# MSP432E401Y register map
Vendor: Texas Instruments; Series: MSP432E4; File version: 3.200
CPU: CM4 r1p2, little endian, no MPU, FPU, 3 interrupt priority bits
Registers are 32-bit, read-write, no defined reset value unless marked. A register's access mark holds for its fields unless they carry their own. Offsets are from the block's base; [hi:lo] are bit positions; {n}, {i} and the like mark numbered series.

## CCM0 — Register map for CCM0 peripheral
Base 0x44030204; register names take the prefix CCM0
0x00 CCMCGREQ — Cryptographic Modules Clock Gating Request

## CRC — Register map for CRC peripheral
Base 0x44030400
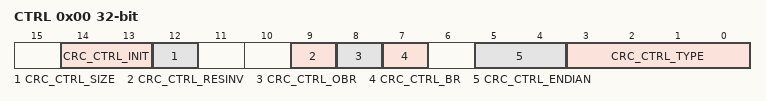
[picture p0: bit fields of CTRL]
0x00 CTRL — CRC Control
  [14:13] CRC_CTRL_INIT — CRC Initialization
    0=CRC_CTRL_INIT_SEED (Use the CRCSEED register context as the starting value); 2=Initialize to all '0s'; 3=Initialize to all '1s'
  [12] CRC_CTRL_SIZE — Input Data Size
  [9] CRC_CTRL_RESINV — Result Inverse Enable
  [8] CRC_CTRL_OBR — Output Reverse Enable
  [7] CRC_CTRL_BR — Bit reverse enable
  [5:4] CRC_CTRL_ENDIAN — Endian Control
    0=CRC_CTRL_ENDIAN_SBHW (Configuration unchanged. (B3, B2, B1, B0)); 1=CRC_CTRL_ENDIAN_SHW (Bytes are swapped in half-words but half-words are not swapped (B2, B3, B0, B1)); 2=CRC_CTRL_ENDIAN_SHWNB (Half-words are swapped but bytes are not swapped in half-word. (B1, B0, B3, B2)); 3=CRC_CTRL_ENDIAN_SBSW (Bytes are swapped in half-words and half-words are swapped. (B0, B1, B2, B3))
  [3:0] CRC_CTRL_TYPE — Operation Type
    0=CRC_CTRL_TYPE_P8055 (Polynomial 0x8005); 1=CRC_CTRL_TYPE_P1021 (Polynomial 0x1021); 2=CRC_CTRL_TYPE_P4C11DB7 (Polynomial 0x4C11DB7); 3=CRC_CTRL_TYPE_P1EDC6F41 (Polynomial 0x1EDC6F41); 8=CRC_CTRL_TYPE_TCPCHKSUM (TCP checksum)
0x10 CRCSEED — CRC SEED/Context
  [31:0] CRC_SEED_SEED — SEED/Context Value
0x14 CRCDIN — CRC Data Input
  [31:0] CRC_DIN_DATAIN — Data Input
0x18 CRCRSLTPP — CRC Post Processing Result
  [31:0] CRC_RSLTPP_RSLTPP — Post Processing Result

## SHAMD5 — Register map for SHAMD5 peripheral
Base 0x44034000; register names take the prefix SHAMD5
0x00 ODIGEST_A — SHA Outer Digest A
  [31:0] SHAMD5_ODIGEST_A_DATA — Digest/Key Data
0x04 ODIGEST_B — SHA Outer Digest B
  [31:0] SHAMD5_ODIGEST_B_DATA — Digest/Key Data
0x08 ODIGEST_C — SHA Outer Digest C
  [31:0] SHAMD5_ODIGEST_C_DATA — Digest/Key Data
0x0C ODIGEST_D — SHA Outer Digest D
  [31:0] SHAMD5_ODIGEST_D_DATA — Digest/Key Data
0x10 ODIGEST_E — SHA Outer Digest E
  [31:0] SHAMD5_ODIGEST_E_DATA — Digest/Key Data
0x14 ODIGEST_F — SHA Outer Digest F
  [31:0] SHAMD5_ODIGEST_F_DATA — Digest/Key Data
0x18 ODIGEST_G — SHA Outer Digest G
  [31:0] SHAMD5_ODIGEST_G_DATA — Digest/Key Data
0x1C ODIGEST_H — SHA Outer Digest H
  [31:0] SHAMD5_ODIGEST_H_DATA — Digest/Key Data
0x20 IDIGEST_A — SHA Inner Digest A
  [31:0] SHAMD5_IDIGEST_A_DATA — Digest/Key Data
0x24 IDIGEST_B — SHA Inner Digest B
  [31:0] SHAMD5_IDIGEST_B_DATA — Digest/Key Data
0x28 IDIGEST_C — SHA Inner Digest C
  [31:0] SHAMD5_IDIGEST_C_DATA — Digest/Key Data
0x2C IDIGEST_D — SHA Inner Digest D
  [31:0] SHAMD5_IDIGEST_D_DATA — Digest/Key Data
0x30 IDIGEST_E — SHA Inner Digest E
  [31:0] SHAMD5_IDIGEST_E_DATA — Digest/Key Data
0x34 IDIGEST_F — SHA Inner Digest F
  [31:0] SHAMD5_IDIGEST_F_DATA — Digest/Key Data
0x38 IDIGEST_G — SHA Inner Digest G
  [31:0] SHAMD5_IDIGEST_G_DATA — Digest/Key Data
0x3C IDIGEST_H — SHA Inner Digest H
  [31:0] SHAMD5_IDIGEST_H_DATA — Digest/Key Data
0x40 DIGEST_COUNT — SHA Digest Count
  [31:0] SHAMD5_DIGEST_COUNT — Digest Count
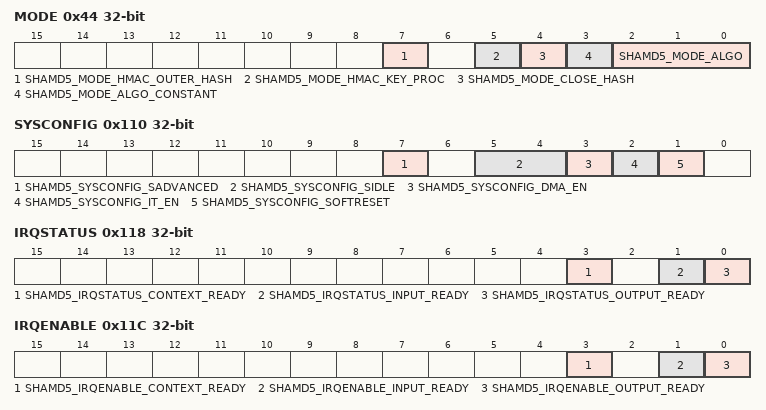
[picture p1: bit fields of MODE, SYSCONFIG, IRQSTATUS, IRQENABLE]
0x44 MODE — SHA Mode
  [7] SHAMD5_MODE_HMAC_OUTER_HASH — HMAC Outer Hash Processing Enable
  [5] SHAMD5_MODE_HMAC_KEY_PROC — HMAC Key Processing Enable
  [4] SHAMD5_MODE_CLOSE_HASH — Performs the padding, the Hash/HMAC will be 'closed' at the end of the block, as per MD5/SHA-1/SHA-2 specification
  [3] SHAMD5_MODE_ALGO_CONSTANT — The initial digest register will be overwritten with the algorithm constants for the selected algorithm when hashing and the initial digest count register will be reset to 0
  [2:0] SHAMD5_MODE_ALGO — Hash Algorithm
    0=SHAMD5_MODE_ALGO_MD5 (MD5); 2=SHAMD5_MODE_ALGO_SHA1 (SHA-1); 4=SHAMD5_MODE_ALGO_SHA224 (SHA-224); 6=SHAMD5_MODE_ALGO_SHA256 (SHA-256)
0x48 LENGTH — SHA Length
  [31:0] SHAMD5_LENGTH — Block Length/Remaining Byte Count
{0x80+4i} DATA_{i}_IN (i=0..15) — SHA Data {i} Input
  [31:0] SHAMD5_DATA_{i}_IN_DATA — Digest/Key Data
0x100 REVISION — SHA Revision
  [31:0] SHAMD5_REVISION — Revision Number
0x110 SYSCONFIG — SHA System Configuration
  [7] SHAMD5_SYSCONFIG_SADVANCED — Advanced Mode Enable
  [5:4] SHAMD5_SYSCONFIG_SIDLE — Sidle mode
    0=SHAMD5_SYSCONFIG_SIDLE_FORCE (Force-idle mode)
  [3] SHAMD5_SYSCONFIG_DMA_EN — uDMA Request Enable
  [2] SHAMD5_SYSCONFIG_IT_EN — Interrupt Enable
  [1] SHAMD5_SYSCONFIG_SOFTRESET — Soft reset
0x114 SYSSTATUS — SHA System Status
  [0] SHAMD5_SYSSTATUS_RESETDONE — Reset done status
0x118 IRQSTATUS — SHA Interrupt Status
  [3] SHAMD5_IRQSTATUS_CONTEXT_READY — Context Ready Status
  [1] SHAMD5_IRQSTATUS_INPUT_READY — Input Ready Status
  [0] SHAMD5_IRQSTATUS_OUTPUT_READY — Output Ready Status
0x11C IRQENABLE — SHA Interrupt Enable
  [3] SHAMD5_IRQENABLE_CONTEXT_READY — Mask for context ready interrupt
  [1] SHAMD5_IRQENABLE_INPUT_READY — Mask for input ready interrupt
  [0] SHAMD5_IRQENABLE_OUTPUT_READY — Mask for output ready interrupt
